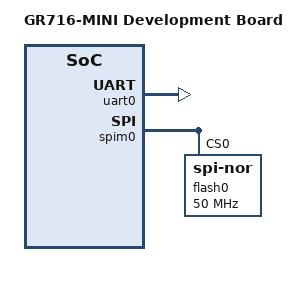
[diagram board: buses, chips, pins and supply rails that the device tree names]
/*
 * Copyright (c) 2019-2020 Cobham Gaisler AB
 *
 * SPDX-License-Identifier: Apache-2.0
 */

/dts-v1/;

#include <mem.h>
#include <gaisler/gr716a.dtsi>

/ {
	model = "GR716-MINI Development Board";
	compatible = "gaisler,gr716a-mini";

	chosen {
		zephyr,console = &uart0;
		zephyr,shell-uart = &uart0;
		zephyr,sram = &dram;
	};
};

&uart0 {
	status = "okay";
};

&spim0 {
	status = "okay";
	/* 256 Mbit SPI flash MX25L25635FZ2I-10G in 8 pin WSON package */
	flash0: flash@0 {
		compatible = "jedec,spi-nor";
		reg = <0>;
		spi-max-frequency = <50000000>;
		size = <DT_SIZE_M(256)>;
		jedec-id = [c2 20 19];
	};
};

&gpio0 {
	status = "okay";
};

&gpio1 {
	status = "okay";
};
